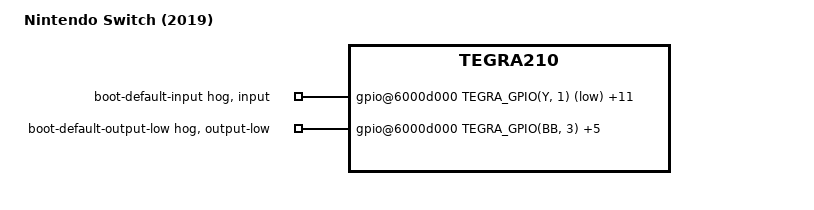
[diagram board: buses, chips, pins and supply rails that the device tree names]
// SPDX-License-Identifier: GPL-2.0
/dts-v1/;

#include "tegra210b01-nx.dtsi"

/ {
	model = "Nintendo Switch (2019)";
	compatible = "nvidia,modin", "nvidia,odin", "nintendo,iowa", "nintendo,nx", "nvidia,tegra210b01", "nvidia,tegra210";

	gpio@6000d000 {
		boot-default-input {
			gpio-hog;
			input;
			gpios = <
				TEGRA_GPIO(Y, 1) GPIO_ACTIVE_LOW /* Home Button (RCM) */
				TEGRA_GPIO(S, 1) GPIO_ACTIVE_LOW /* Charger IC (BQ24193) Battery Charge Status */
				TEGRA_GPIO(S, 3) GPIO_ACTIVE_LOW /* Gamecard Detect */
				TEGRA_GPIO(Z, 3) GPIO_ACTIVE_LOW /* SD Card Write Protected */
				TEGRA_GPIO(H, 2) GPIO_ACTIVE_LOW /* Wi-Fi Wake Host */
				TEGRA_GPIO(K, 0) GPIO_ACTIVE_HIGH /* Bluetooth Gpio2 */
				TEGRA_GPIO(K, 1) GPIO_ACTIVE_HIGH /* Bluetooth Gpio3 */
				TEGRA_GPIO(K, 2) GPIO_ACTIVE_HIGH /* Bluetooth Gpio4 */
				TEGRA_GPIO(V, 3) GPIO_ACTIVE_LOW /* Unused */
				TEGRA_GPIO(P, 0) GPIO_ACTIVE_LOW /* SDEV Odin/Modin */
				TEGRA_GPIO(BB, 2) GPIO_ACTIVE_HIGH /* Ram Code 3 */
				TEGRA_GPIO(CC, 2) GPIO_ACTIVE_HIGH /* Ram Code 2 */
			>;
			line-name = "boot-default-input";
		};

		boot-default-output-low {
			gpio-hog;
			output-low;
			gpios = <
				TEGRA_GPIO(BB, 3) GPIO_ACTIVE_HIGH /* Gamecard Reset */
				TEGRA_GPIO(V, 5) GPIO_ACTIVE_HIGH /* USB-PD (BM92T36) Reset */
				TEGRA_GPIO(J, 5) GPIO_ACTIVE_HIGH /* Charger IC (BQ24193) Charge Select 1 */
				TEGRA_GPIO(L, 0) GPIO_ACTIVE_HIGH /* Charger IC (BQ24193) Charge Select 2 */
				TEGRA_GPIO(H, 0) GPIO_ACTIVE_HIGH /* Wi-Fi RF Disable */
				TEGRA_GPIO(H, 7) GPIO_ACTIVE_HIGH /* TODO: What's this? Bluetooth Gpio5 */
			>;
			line-name = "boot-default-output-low";
		};
	};
};
